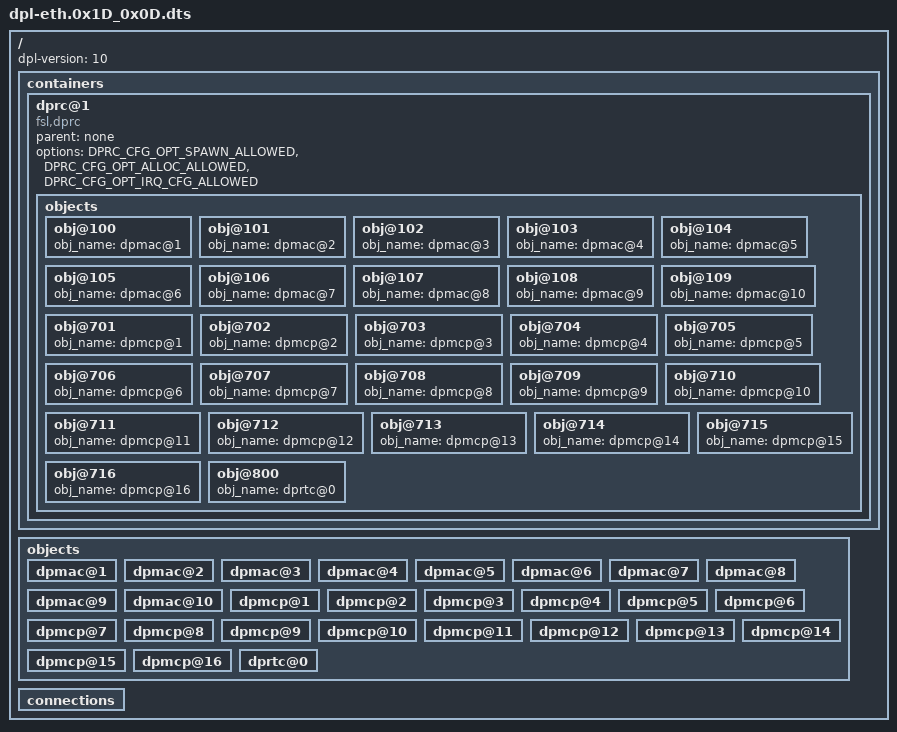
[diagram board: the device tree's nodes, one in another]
/*
 * Copyright 2015 Freescale Semiconductor, Inc.
 * "Bootstrap DPL" for ls1088a featuring SerDes 0x1D_0x0D.
 * This together with the available DPMCP objects should be enough to boot Linux
 * and to allow the dynamic addition of other objects to the Linux container,
 * using the 'restool' utility.
 */

/dts-v1/;
/ {
	dpl-version = <10>;
	/*****************************************************************
	 * Containers
	 *****************************************************************/
	containers {
		dprc@1 {
			compatible = "fsl,dprc";
			parent = "none";
			options = "DPRC_CFG_OPT_SPAWN_ALLOWED" , "DPRC_CFG_OPT_ALLOC_ALLOWED", "DPRC_CFG_OPT_IRQ_CFG_ALLOWED";
			objects {
				/* ------------- MACs --------------*/
				obj@100 {
					obj_name = "dpmac@1";
				};
				obj@101 {
					obj_name = "dpmac@2";
				};
				obj@102 {
					obj_name = "dpmac@3";
				};
				obj@103 {
					obj_name = "dpmac@4";
				};
				obj@104 {
					obj_name = "dpmac@5";
				};
				obj@105 {
					obj_name = "dpmac@6";
				};
				obj@106 {
					obj_name = "dpmac@7";
				};
				obj@107 {
					obj_name = "dpmac@8";
				};
				obj@108 {
					obj_name = "dpmac@9";
				};
				obj@109 {
					obj_name = "dpmac@10";
				};

				/* ------------ DPMCPs --------------*/
				obj@701 {
					obj_name="dpmcp@1";
				};
				obj@702 {
					obj_name="dpmcp@2";
				};
				obj@703 {
					obj_name="dpmcp@3";
				};
				obj@704 {
					obj_name="dpmcp@4";
				};
				obj@705 {
					obj_name="dpmcp@5";
				};
				obj@706 {
					obj_name="dpmcp@6";
				};
				obj@707 {
					obj_name="dpmcp@7";
				};
				obj@708 {
					obj_name="dpmcp@8";
				};
				obj@709 {
					obj_name="dpmcp@9";
				};
				obj@710 {
					obj_name="dpmcp@10";
				};
				obj@711 {
					obj_name="dpmcp@11";
				};
				obj@712 {
					obj_name="dpmcp@12";
				};
				obj@713 {
						obj_name="dpmcp@13";
				};
				obj@714 {
						obj_name="dpmcp@14";
				};
				obj@715 {
						obj_name="dpmcp@15";
				};
				obj@716 {
						obj_name="dpmcp@16";
				};

				/* ------------ DPRTC --------------*/
				obj@800 {
					obj_name="dprtc@0";
				};
			};
		};
	};

	/*****************************************************************
	 * Objects
	 *****************************************************************/
	objects {
		/* ------------ DPMAC --------------*/
		dpmac@1 {
		};
		dpmac@2 {
		};
		dpmac@3 {
		};
		dpmac@4 {
		};
		dpmac@5 {
		};
		dpmac@6 {
		};
		dpmac@7 {
		};
		dpmac@8 {
		};
		dpmac@9 {
		};
		dpmac@10 {
		};

		/* ------------ DPMCP --------------*/
		dpmcp@1 {
		};
		dpmcp@2 {
		};
		dpmcp@3 {
		};
		dpmcp@4 {
		};
		dpmcp@5 {
		};
		dpmcp@6 {
		};
		dpmcp@7 {
		};
		dpmcp@8 {
		};
		dpmcp@9 {
		};
		dpmcp@10 {
		};
		dpmcp@11 {
		};
		dpmcp@12 {
		};
		dpmcp@13 {
		};
		dpmcp@14 {
		};
		dpmcp@15 {
		};
		dpmcp@16 {
		};

		/* ------------ DPRTC --------------*/
		dprtc@0 {
		};
	};

	/*****************************************************************
	 * Connections
	 *****************************************************************/
	connections {
	};
};
